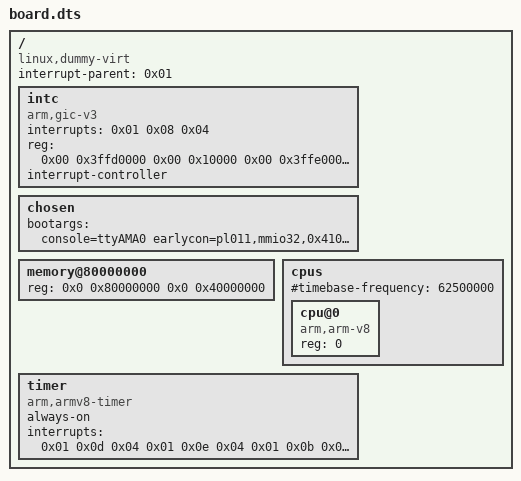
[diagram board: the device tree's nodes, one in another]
/dts-v1/;

/ {
    #address-cells = <2>;
    #size-cells = <2>;
    compatible = "linux,dummy-virt";
    interrupt-parent = <0x01>;

    intc {
        #address-cells = <0x02>;
        interrupts = <0x01 0x08 0x04>;
        #size-cells = <0x02>;
        compatible = "arm,gic-v3";
        ranges;
        #interrupt-cells = <0x03>;
        reg = <0x00 0x3ffd0000 0x00 0x10000 0x00 0x3ffe0000 0x00 0x20000>;
        phandle = <0x01>;
        interrupt-controller;
    };

    chosen {
        bootargs = "console=ttyAMA0 earlycon=pl011,mmio32,0x41000000 clk_ignore_unused root=";
    };

    memory@80000000 {
        device_type = "memory";
        reg = <0x0 0x80000000 0x0 0x40000000>; /* 1Gb RAM */
    };

    cpus {
        #address-cells = <1>;
        #size-cells = <0>;
        #timebase-frequency = <62500000>;

        cpu@0 {
            device_type = "cpu";
            compatible = "arm,arm-v8";
            reg = <0>;
        };
    };

    timer {
        always-on;
        interrupts = <0x01 0x0d 0x04 0x01 0x0e 0x04 0x01 0x0b 0x04 0x01 0x0c 0x04>;
        compatible = "arm,armv8-timer";
    };
};
